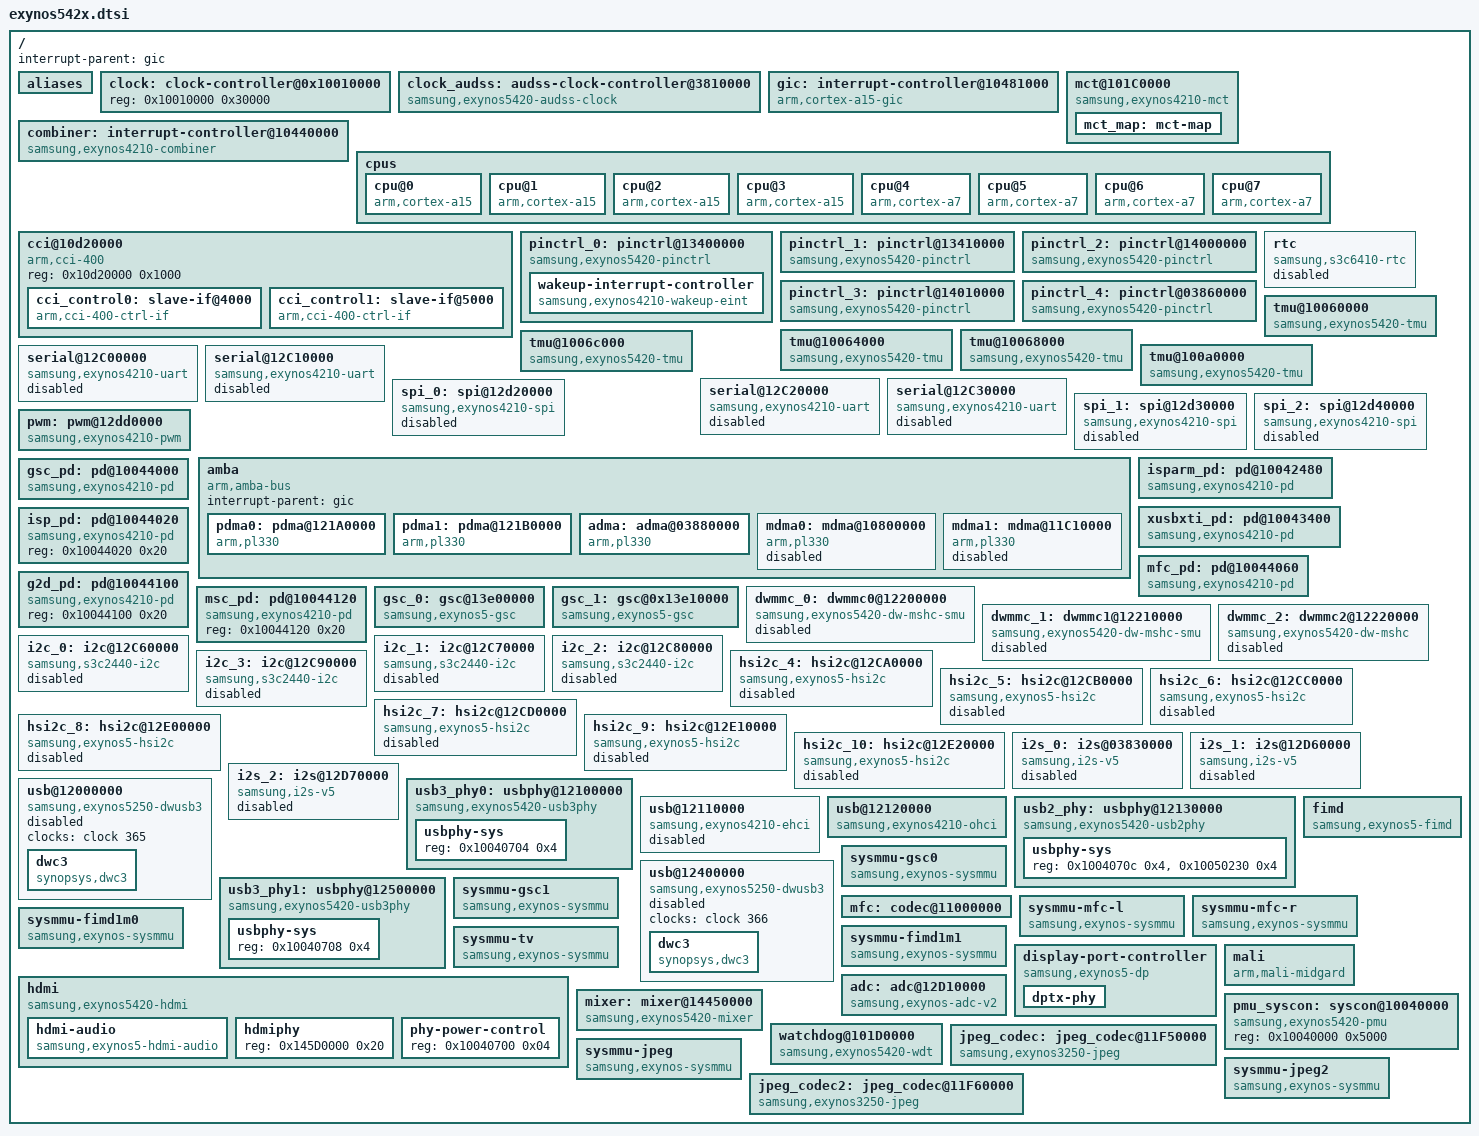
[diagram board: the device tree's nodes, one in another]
/*
 * SAMSUNG EXYNOS542x SoC device tree source
 *
 * Copyright (c) 2013 Samsung Electronics Co., Ltd.
 *		http://www.samsung.com
 *
 * This program is free software; you can redistribute it and/or modify
 * it under the terms of the GNU General Public License version 2 as
 * published by the Free Software Foundation.
*/

#include "skeleton.dtsi"
#include "exynos542x-pinctrl.dtsi"

#include <dt-bindings/clk/exynos-audss-clk.h>

/ {
	interrupt-parent = <&gic>;

	aliases {
		pinctrl0 = &pinctrl_0;
		pinctrl1 = &pinctrl_1;
		pinctrl2 = &pinctrl_2;
		pinctrl3 = &pinctrl_3;
		pinctrl4 = &pinctrl_4;
		mshc0 = &dwmmc_0;
		mshc1 = &dwmmc_1;
		mshc2 = &dwmmc_2;
		gsc0 = &gsc_0;
		gsc1 = &gsc_1;
		i2c0 = &i2c_0;
		i2c1 = &i2c_1;
		i2c2 = &i2c_2;
		i2c3 = &i2c_3;
		i2c4 = &hsi2c_4;
		i2c5 = &hsi2c_5;
		i2c6 = &hsi2c_6;
		i2c7 = &hsi2c_7;
		i2c8 = &hsi2c_8;
		i2c9 = &hsi2c_9;
		i2c10 = &hsi2c_10;
		usb3phy0 = &usb3_phy0;
		usb3phy1 = &usb3_phy1;
		spi0 = &spi_0;
		spi1 = &spi_1;
		spi2 = &spi_2;
	};

	clock: clock-controller@0x10010000 {
		reg = <0x10010000 0x30000>;
		#clock-cells = <1>;
	};

	clock_audss: audss-clock-controller@3810000 {
		compatible = "samsung,exynos5420-audss-clock";
		reg = <0x03810000 0x0C>;
		#clock-cells = <1>;
		clocks = <&clock 148>;
		clock-names = "sclk_audio";
	};

	gic:interrupt-controller@10481000 {
		compatible = "arm,cortex-a15-gic", "arm,cortex-a9-gic";
		#interrupt-cells = <3>;
		#address-cells = <0>;
		#size-cells = <0>;
		interrupt-controller;
		reg = <0x10481000 0x1000>,
		      <0x10482000 0x1000>,
		      <0x10484000 0x2000>,
		      <0x10486000 0x2000>;
		interrupts = <1 9 0xf04>;
	};

	mct@101C0000 {
		compatible = "samsung,exynos4210-mct";
		reg = <0x101C0000 0xb00>;
		interrupt-controller;
		#interrups-cells = <2>;
		interrupt-parent = <&mct_map>;
		interrupts = <0 0>, <1 0>, <2 0>, <3 0>,
			     <4 0>, <5 0>, <6 0>, <7 0>,
			     <8 0>, <9 0>, <10 0>, <11 0>;
		clocks = <&clock 1>, <&clock 315>;
		clock-names = "fin_pll", "mct";

		mct_map: mct-map {
			#interrupt-cells = <2>;
			#address-cells = <0>;
			#size-cells = <0>;
			interrupt-map = <0x0 0 &combiner 23 3>,
					<0x1 0 &combiner 23 4>,
					<0x2 0 &combiner 25 2>,
					<0x3 0 &combiner 25 3>,
					<0x4 0 &gic 0 120 0>,
					<0x5 0 &gic 0 121 0>,
					<0x6 0 &gic 0 122 0>,
					<0x7 0 &gic 0 123 0>,
					<0x8 0 &gic 0 128 0>,
					<0x9 0 &gic 0 129 0>,
					<0xa 0 &gic 0 130 0>,
					<0xb 0 &gic 0 131 0>;
		};
	};

	combiner:interrupt-controller@10440000 {
		compatible = "samsung,exynos4210-combiner";
		#interrupt-cells = <2>;
		interrupt-controller;
		samsung,combiner-nr = <32>;
		reg = <0x10440000 0x1000>;
		interrupts = <0 0 0>, <0 1 0>, <0 2 0>, <0 3 0>,
			     <0 4 0>, <0 5 0>, <0 6 0>, <0 7 0>,
			     <0 8 0>, <0 9 0>, <0 10 0>, <0 11 0>,
			     <0 12 0>, <0 13 0>, <0 14 0>, <0 15 0>,
			     <0 16 0>, <0 17 0>, <0 18 0>, <0 19 0>,
			     <0 20 0>, <0 21 0>, <0 22 0>, <0 23 0>,
			     <0 24 0>, <0 25 0>, <0 26 0>, <0 27 0>,
			     <0 28 0>, <0 29 0>, <0 30 0>, <0 31 0>;
	};

	cpus {
		#address-cells = <1>;
		#size-cells = <0>;

		cpu@0 {
			device_type = "cpu";
			compatible = "arm,cortex-a15";
			reg = <0>;
			cci-control-port = <&cci_control1>;
		};
		cpu@1 {
			device_type = "cpu";
			compatible = "arm,cortex-a15";
			reg = <1>;
			cci-control-port = <&cci_control1>;
		};
		cpu@2 {
			device_type = "cpu";
			compatible = "arm,cortex-a15";
			reg = <2>;
			cci-control-port = <&cci_control1>;
		};
		cpu@3 {
			device_type = "cpu";
			compatible = "arm,cortex-a15";
			reg = <3>;
			cci-control-port = <&cci_control1>;
		};
		cpu@4 {
			device_type = "cpu";
			compatible = "arm,cortex-a7";
			reg = <0x100>;
			cci-control-port = <&cci_control0>;
		};
		cpu@5 {
			device_type = "cpu";
			compatible = "arm,cortex-a7";
			reg = <0x101>;
			cci-control-port = <&cci_control0>;
		};
		cpu@6 {
			device_type = "cpu";
			compatible = "arm,cortex-a7";
			reg = <0x102>;
			cci-control-port = <&cci_control0>;
		};
		cpu@7 {
			device_type = "cpu";
			compatible = "arm,cortex-a7";
			reg = <0x103>;
			cci-control-port = <&cci_control0>;
		};
	};

	cci@10d20000 {
		compatible = "arm,cci-400";
		#address-cells = <1>;
		#size-cells = <1>;
		reg = <0x10d20000 0x1000>;
		ranges = <0x0 0x10d20000 0x6000>;

		cci_control0: slave-if@4000 {
			compatible = "arm,cci-400-ctrl-if";
			interface-type = "ace";
			reg = <0x4000 0x1000>;
		};

		cci_control1: slave-if@5000 {
			compatible = "arm,cci-400-ctrl-if";
			interface-type = "ace";
			reg = <0x5000 0x1000>;
		};
	};

	pinctrl_0: pinctrl@13400000 {
		compatible = "samsung,exynos5420-pinctrl";
		reg = <0x13400000 0x1000>;
		interrupts = <0 45 0>;

		wakeup-interrupt-controller {
			compatible = "samsung,exynos4210-wakeup-eint";
			interrupt-parent = <&gic>;
			interrupts = <0 32 0>;
		};
	};

	pinctrl_1: pinctrl@13410000 {
		compatible = "samsung,exynos5420-pinctrl";
		reg = <0x13410000 0x1000>;
		interrupts = <0 78 0>;
	};

	pinctrl_2: pinctrl@14000000 {
		compatible = "samsung,exynos5420-pinctrl";
		reg = <0x14000000 0x1000>;
		interrupts = <0 46 0>;
	};

	pinctrl_3: pinctrl@14010000 {
		compatible = "samsung,exynos5420-pinctrl";
		reg = <0x14010000 0x1000>;
		interrupts = <0 50 0>;
	};

	pinctrl_4: pinctrl@03860000 {
		compatible = "samsung,exynos5420-pinctrl";
		reg = <0x03860000 0x1000>;
		interrupts = <0 47 0>;
	};

	rtc {
		compatible = "samsung,s3c6410-rtc";
		reg = <0x101E0000 0x100>;
		interrupts = <0 43 0>, <0 44 0>;
		clocks = <&clock 317>;
		clock-names = "rtc";
		status = "disabled";
	};

	/* tmu for CPU0 */
	tmu@10060000 {
		compatible = "samsung,exynos5420-tmu";
		reg = <0x10060000 0x100>;
		interrupts = <0 65 0>;
		clocks = <&clock 318>;
		clock-names = "tmu_apbif";
	};

	/* tmu for CPU1 */
	tmu@10064000 {
		compatible = "samsung,exynos5420-tmu";
		reg = <0x10064000 0x100>;
		interrupts = <0 183 0>;
		clocks = <&clock 318>;
		clock-names = "tmu_apbif";
	};

	/* tmu for CPU2 */
	tmu@10068000 {
		compatible = "samsung,exynos5420-tmu";
		/* 2nd reg is for the misplaced TRIMINFO register */
		reg = <0x10068000 0x100>, <0x1006c000 0x4>;
		interrupts = <0 184 0>;
		clocks = <&clock 318>;
		clock-names = "tmu_apbif";
	};

	/* tmu for CPU3 */
	tmu@1006c000 {
		compatible = "samsung,exynos5420-tmu";
		/* 2nd reg is for the misplaced TRIMINFO register */
		reg = <0x1006c000 0x100>, <0x100a0000 0x4>;
		interrupts = <0 185 0>;
		clocks = <&clock 318>, <&clock 319>;
		clock-names = "tmu_apbif", "tmu_apbif_triminfo";
	};

	/* tmu for GPU */
	tmu@100a0000 {
		compatible = "samsung,exynos5420-tmu";
		/* 2nd reg is for the misplaced TRIMINFO register */
		reg = <0x100a0000 0x100>, <0x10068000 0x4>;
		interrupts = <0 215 0>;
		clocks = <&clock 319>, <&clock 318>;
		clock-names = "tmu_apbif", "tmu_apbif_triminfo";
	};

	serial@12C00000 {
		compatible = "samsung,exynos4210-uart";
		reg = <0x12C00000 0x100>;
		interrupts = <0 51 0>;
		clocks = <&clock 257>, <&clock 128>;
		clock-names = "uart", "clk_uart_baud0";
		status = "disabled";
	};

	serial@12C10000 {
		compatible = "samsung,exynos4210-uart";
		reg = <0x12C10000 0x100>;
		interrupts = <0 52 0>;
		clocks = <&clock 258>, <&clock 129>;
		clock-names = "uart", "clk_uart_baud0";
		status = "disabled";
	};

	serial@12C20000 {
		compatible = "samsung,exynos4210-uart";
		reg = <0x12C20000 0x100>;
		interrupts = <0 53 0>;
		clocks = <&clock 259>, <&clock 130>;
		clock-names = "uart", "clk_uart_baud0";
		status = "disabled";
	};

	serial@12C30000 {
		compatible = "samsung,exynos4210-uart";
		reg = <0x12C30000 0x100>;
		interrupts = <0 54 0>;
		clocks = <&clock 260>, <&clock 131>;
		clock-names = "uart", "clk_uart_baud0";
		status = "disabled";
	};

	spi_0: spi@12d20000 {
		compatible = "samsung,exynos4210-spi";
		reg = <0x12d20000 0x100>;
		interrupts = <0 66 0>;
		dmas = <&pdma0 5
			&pdma0 4>;
		dma-names = "tx", "rx";
		#address-cells = <1>;
		#size-cells = <0>;
		pinctrl-names = "default";
		pinctrl-0 = <&spi0_bus>;
		clocks = <&clock 271>, <&clock 135>;
		clock-names = "spi", "spi_busclk0";
		status = "disabled";
	};

	spi_1: spi@12d30000 {
		compatible = "samsung,exynos4210-spi";
		reg = <0x12d30000 0x100>;
		interrupts = <0 67 0>;
		dmas = <&pdma1 5
			&pdma1 4>;
		dma-names = "tx", "rx";
		#address-cells = <1>;
		#size-cells = <0>;
		pinctrl-names = "default";
		pinctrl-0 = <&spi1_bus>;
		clocks = <&clock 272>, <&clock 136>;
		clock-names = "spi", "spi_busclk0";
		status = "disabled";
	};

	spi_2: spi@12d40000 {
		compatible = "samsung,exynos4210-spi";
		reg = <0x12d40000 0x100>;
		interrupts = <0 68 0>;
		dmas = <&pdma0 7
			&pdma0 6>;
		dma-names = "tx", "rx";
		#address-cells = <1>;
		#size-cells = <0>;
		pinctrl-names = "default";
		pinctrl-0 = <&spi2_bus>;
		clocks = <&clock 273>, <&clock 137>;
		clock-names = "spi", "spi_busclk0";
		status = "disabled";
	};

	pwm: pwm@12dd0000 {
		compatible = "samsung,exynos4210-pwm";
		reg = <0x12dd0000 0x100>;
		samsung,pwm-outputs = <0>, <1>, <2>, <3>;
		#pwm-cells = <3>;
		clocks = <&clock 278>;
		clock-names = "timers";
	};

	amba {
		#address-cells = <1>;
		#size-cells = <1>;
		compatible = "arm,amba-bus";
		interrupt-parent = <&gic>;
		ranges;

		pdma0: pdma@121A0000 {
			compatible = "arm,pl330", "arm,primecell";
			reg = <0x121A0000 0x1000>;
			interrupts = <0 34 0>;
			clocks = <&clock 361>;
			clock-names = "apb_pclk";
			#dma-cells = <1>;
			#dma-channels = <8>;
			#dma-requests = <32>;
		};

		pdma1: pdma@121B0000 {
			compatible = "arm,pl330", "arm,primecell";
			reg = <0x121B0000 0x1000>;
			interrupts = <0 35 0>;
			clocks = <&clock 362>;
			clock-names = "apb_pclk";
			#dma-cells = <1>;
			#dma-channels = <8>;
			#dma-requests = <32>;
		};

		adma: adma@03880000 {
			compatible = "arm,pl330", "arm,primecell";
			reg = <0x03880000 0x1000>;
			interrupts = <0 110 0>;
			clocks = <&clock_audss EXYNOS_ADMA>;
			clock-names = "apb_pclk";
			#dma-cells = <1>;
			#dma-channels = <6>;
			#dma-requests = <16>;
		};

		mdma0: mdma@10800000 {
			compatible = "arm,pl330", "arm,primecell";
			reg = <0x10800000 0x1000>;
			interrupts = <0 33 0>;
			clocks = <&clock 473>;
			clock-names = "apb_pclk";
			#dma-cells = <1>;
			#dma-channels = <8>;
			#dma-requests = <1>;
			status = "disabled";
		};

		mdma1: mdma@11C10000 {
			compatible = "arm,pl330", "arm,primecell";
			reg = <0x11C10000 0x1000>;
			interrupts = <0 124 0>;
			clocks = <&clock 442>;
			clock-names = "apb_pclk";
			#dma-cells = <1>;
			#dma-channels = <8>;
			#dma-requests = <1>;
			status = "disabled";
		};
	};

	isparm_pd: pd@10042480 {
		compatible = "samsung,exynos4210-pd";
		reg = <0x10042480 0x20>;
		enable = <0x1>;
	};

	xusbxti_pd: pd@10043400 {
		compatible = "samsung,exynos4210-pd";
		reg = <0x10043400 0x20>;
		enable = <0x1>;
	};

	gsc_pd: pd@10044000 {
		compatible = "samsung,exynos4210-pd";
		reg = <0x10044000 0x20>;
		clocks = <&clock 1>, <&clock 1032>, <&clock 1033>,
			 <&clock 2050>, <&clock 1034>, <&clock 1035>,
			 <&clock 2051>;
		clock-names = "oscclk", "pclk0", "clk0", "dclk0",
			      "pclk1", "clk1", "dclk1";
	};

	isp_pd: pd@10044020 {
		compatible = "samsung,exynos4210-pd";
		reg = <0x10044020 0x20>;
	};

	mfc_pd: pd@10044060 {
		compatible = "samsung,exynos4210-pd";
		reg = <0x10044060 0x20>;
		clocks = <&clock 1>, <&clock 1030>, <&clock 1031>,
			 <&clock 2049>;
		clock-names = "oscclk", "pclk0", "clk0" , "dclk0";
	};

	g2d_pd: pd@10044100 {
		compatible = "samsung,exynos4210-pd";
		reg = <0x10044100 0x20>;
	};

	msc_pd: pd@10044120 {
		compatible = "samsung,exynos4210-pd";
		reg = <0x10044120 0x20>;
	};

	gsc_0:  gsc@13e00000 {
		compatible = "samsung,exynos5-gsc";
		reg = <0x13e00000 0x1000>;
		interrupts = <0 85 0>;
		clocks = <&clock 465>;
		clock-names = "gscl";
		samsung,power-domain = <&gsc_pd>;
	};

	gsc_1:  gsc@0x13e10000 {
		compatible = "samsung,exynos5-gsc";
		reg = <0x13e10000 0x1000>;
		interrupts = <0 86 0>;
		clocks = <&clock 466>;
		clock-names = "gscl";
		samsung,power-domain = <&gsc_pd>;
	};

	dwmmc_0: dwmmc0@12200000 {
		compatible = "samsung,exynos5420-dw-mshc-smu";
		reg = <0x12200000 0x2000>;
		interrupts = <0 75 0>;
		#address-cells = <1>;
		#size-cells = <0>;
		clocks = <&clock 351>, <&clock 132>;
		clock-names = "biu", "ciu";
		status = "disabled";
	};

	dwmmc_1: dwmmc1@12210000 {
		compatible = "samsung,exynos5420-dw-mshc-smu";
		reg = <0x12210000 0x2000>;
		interrupts = <0 76 0>;
		#address-cells = <1>;
		#size-cells = <0>;
		clocks = <&clock 352>, <&clock 133>;
		clock-names = "biu", "ciu";
		status = "disabled";
	};

	dwmmc_2: dwmmc2@12220000 {
		compatible = "samsung,exynos5420-dw-mshc";
		reg = <0x12220000 0x1000>;
		interrupts = <0 77 0>;
		#address-cells = <1>;
		#size-cells = <0>;
		clocks = <&clock 353>, <&clock 134>;
		clock-names = "biu", "ciu";
		status = "disabled";
	};

	i2c_0: i2c@12C60000 {
		compatible = "samsung,s3c2440-i2c";
		reg = <0x12C60000 0x100>;
		interrupts = <0 56 0>;
		#address-cells = <1>;
		#size-cells = <0>;
		pinctrl-names = "default";
		pinctrl-0 = <&i2c0_bus>;
		clocks = <&clock 261>;
		clock-names = "i2c";
		status = "disabled";
	};

	i2c_1: i2c@12C70000 {
		compatible = "samsung,s3c2440-i2c";
		reg = <0x12C70000 0x100>;
		interrupts = <0 57 0>;
		#address-cells = <1>;
		#size-cells = <0>;
		pinctrl-names = "default";
		pinctrl-0 = <&i2c1_bus>;
		clocks = <&clock 262>;
		clock-names = "i2c";
		status = "disabled";
	};

	i2c_2: i2c@12C80000 {
		compatible = "samsung,s3c2440-i2c";
		reg = <0x12C80000 0x100>;
		interrupts = <0 58 0>;
		#address-cells = <1>;
		#size-cells = <0>;
		pinctrl-names = "default";
		pinctrl-0 = <&i2c2_bus>;
		clocks = <&clock 263>;
		clock-names = "i2c";
		status = "disabled";
	};

	i2c_3: i2c@12C90000 {
		compatible = "samsung,s3c2440-i2c";
		reg = <0x12C90000 0x100>;
		interrupts = <0 59 0>;
		#address-cells = <1>;
		#size-cells = <0>;
		pinctrl-names = "default";
		pinctrl-0 = <&i2c3_bus>;
		clocks = <&clock 264>;
		clock-names = "i2c";
		status = "disabled";
	};

	hsi2c_4: hsi2c@12CA0000 {
		compatible = "samsung,exynos5-hsi2c";
		reg = <0x12CA0000 0x1000>;
		interrupts = <0 60 0>;
		#address-cells = <1>;
		#size-cells = <0>;
		pinctrl-names = "default";
		pinctrl-0 = <&i2c4_hs_bus>;
		clocks = <&clock 265>;
		clock-names = "hsi2c";
		status = "disabled";
	};

	hsi2c_5: hsi2c@12CB0000 {
		compatible = "samsung,exynos5-hsi2c";
		reg = <0x12CB0000 0x1000>;
		interrupts = <0 61 0>;
		#address-cells = <1>;
		#size-cells = <0>;
		pinctrl-names = "default";
		pinctrl-0 = <&i2c5_hs_bus>;
		clocks = <&clock 266>;
		clock-names = "hsi2c";
		status = "disabled";
	};

	hsi2c_6: hsi2c@12CC0000 {
		compatible = "samsung,exynos5-hsi2c";
		reg = <0x12CC0000 0x1000>;
		interrupts = <0 62 0>;
		#address-cells = <1>;
		#size-cells = <0>;
		pinctrl-names = "default";
		pinctrl-0 = <&i2c6_hs_bus>;
		clocks = <&clock 267>;
		clock-names = "hsi2c";
		status = "disabled";
	};

	hsi2c_7: hsi2c@12CD0000 {
		compatible = "samsung,exynos5-hsi2c";
		reg = <0x12CD0000 0x1000>;
		interrupts = <0 63 0>;
		#address-cells = <1>;
		#size-cells = <0>;
		pinctrl-names = "default";
		pinctrl-0 = <&i2c7_hs_bus>;
		clocks = <&clock 268>;
		clock-names = "hsi2c";
		status = "disabled";
	};

	hsi2c_8: hsi2c@12E00000 {
		compatible = "samsung,exynos5-hsi2c";
		reg = <0x12E00000 0x1000>;
		interrupts = <0 87 0>;
		#address-cells = <1>;
		#size-cells = <0>;
		pinctrl-names = "default";
		pinctrl-0 = <&i2c8_hs_bus>;
		clocks = <&clock 280>;
		clock-names = "hsi2c";
		status = "disabled";
	};

	hsi2c_9: hsi2c@12E10000 {
		compatible = "samsung,exynos5-hsi2c";
		reg = <0x12E10000 0x1000>;
		interrupts = <0 88 0>;
		#address-cells = <1>;
		#size-cells = <0>;
		pinctrl-names = "default";
		pinctrl-0 = <&i2c9_hs_bus>;
		clocks = <&clock 281>;
		clock-names = "hsi2c";
		status = "disabled";
	};

	hsi2c_10: hsi2c@12E20000 {
		compatible = "samsung,exynos5-hsi2c";
		reg = <0x12E20000 0x1000>;
		interrupts = <0 203 0>;
		#address-cells = <1>;
		#size-cells = <0>;
		pinctrl-names = "default";
		pinctrl-0 = <&i2c10_hs_bus>;
		clocks = <&clock 282>;
		clock-names = "hsi2c";
		status = "disabled";
	};

	i2s_0: i2s@03830000 {
		compatible = "samsung,i2s-v5";
		reg = <0x03830000 0x100>;
		dmas = <&adma 0
			&adma 2
			&adma 1>;
		dma-names = "tx", "rx", "tx-sec";
		clocks = <&clock_audss EXYNOS_I2S_BUS>,
			<&clock_audss EXYNOS_I2S_BUS>,
			<&clock_audss EXYNOS_SCLK_I2S>;
		clock-names = "iis", "i2s_opclk0", "i2s_opclk1";
		samsung,supports-6ch;
		samsung,supports-rstclr;
		samsung,supports-secdai;
		samsung,supports-tdm;
		samsung,idma-addr = <0x03000000>;
		pinctrl-names = "default";
		pinctrl-0 = <&i2s0_bus>;
		status = "disabled";
	};

	i2s_1: i2s@12D60000 {
		compatible = "samsung,i2s-v5";
		reg = <0x12D60000 0x100>;
		dmas = <&pdma1 12
			&pdma1 11>;
		dma-names = "tx", "rx";
		clocks = <&clock 274>, <&clock 138>;
		clock-names = "iis", "i2s_opclk0";
		pinctrl-names = "default";
		pinctrl-0 = <&i2s1_bus>;
		status = "disabled";
	};

	i2s_2: i2s@12D70000 {
		compatible = "samsung,i2s-v5";
		reg = <0x12D70000 0x100>;
		dmas = <&pdma0 12
			&pdma0 11>;
		dma-names = "tx", "rx";
		clocks = <&clock 275>, <&clock 139>;
		clock-names = "iis", "i2s_opclk0";
		pinctrl-names = "default";
		pinctrl-0 = <&i2s2_bus>;
		status = "disabled";
	};

	usb@12000000 {
		compatible = "samsung,exynos5250-dwusb3";
		clocks = <&clock 365>;
		clock-names = "usbdrd30";
		#address-cells = <1>;
		#size-cells = <1>;
		ranges;
		status = "disabled";

		dwc3 {
			compatible = "synopsys,dwc3";
			reg = <0x12000000 0x10000>;
			interrupts = <0 72 0>;
			usb3-phy = <&usb3_phy0>;
		};
	};

	usb3_phy0: usbphy@12100000 {
		compatible = "samsung,exynos5420-usb3phy";
		reg = <0x12100000 0x100>;
		clocks = <&clock 1>, <&clock 365>;
		clock-names = "ext_xtal", "usbdrd30";
		#address-cells = <1>;
		#size-cells = <1>;
		ranges;

		usbphy-sys {
			reg = <0x10040704 0x4>;
		};
	};

	usb@12110000 {
		compatible = "samsung,exynos4210-ehci";
		reg = <0x12110000 0x100>;
		interrupts = <0 71 0>;
		clocks = <&clock 364>;
		clock-names = "usbhost";
		status = "disabled";
	};

	usb@12120000 {
		compatible = "samsung,exynos4210-ohci";
		reg = <0x12120000 0x100>;
		interrupts = <0 71 0>;
		clocks = <&clock 364>;
		clock-names = "usbhost";
	};

	usb2_phy: usbphy@12130000 {
		compatible = "samsung,exynos5420-usb2phy";
		reg = <0x12130000 0x100>;
		clocks = <&clock 1>, <&clock 364>;
		clock-names = "ext_xtal", "usbhost";
		#address-cells = <1>;
		#size-cells = <1>;
		ranges;

		usbphy-sys {
			reg = <0x1004070c 0x4>,
			      <0x10050230 0x4>;
		};
	};

	usb@12400000 {
		compatible = "samsung,exynos5250-dwusb3";
		clocks = <&clock 366>;
		clock-names = "usbdrd30";
		#address-cells = <1>;
		#size-cells = <1>;
		ranges;
		status = "disabled";

		dwc3 {
			compatible = "synopsys,dwc3";
			reg = <0x12400000 0x10000>;
			interrupts = <0 73 0>;
			usb3-phy = <&usb3_phy1>;
		};
	};

	usb3_phy1: usbphy@12500000 {
		compatible = "samsung,exynos5420-usb3phy";
		reg = <0x12500000 0x100>;
		clocks = <&clock 1>, <&clock 366>;
		clock-names = "ext_xtal", "usbdrd30";
		#address-cells = <1>;
		#size-cells = <1>;
		ranges;

		usbphy-sys {
			reg = <0x10040708 0x4>;
		};
	};

	fimd: fimd {
		compatible = "samsung,exynos5-fimd";
		interrupt-parent = <&combiner>;
		reg = <0x14400000 0x40000>;
		interrupts = <18 5>, <18 4>, <18 6>;
		clocks = <&clock 147>, <&clock 421>, <&clock 1024>,
							<&clock 2>;
		clock-names = "sclk_fimd", "fimd", "mout_fimd",
							"sclk_mout_fimd";
	};

	sysmmu-gsc0 {
		mmuname = "gsc0";
		reg = <0x13E80000 0x1000>;
		compatible = "samsung,exynos-sysmmu";
		interrupt-parent = <&combiner>;
		interrupts = <2 0>;
		mmu-master = <&gsc_0>;
		clocks = <&clock 461>, <&clock 465>;
		clock-names = "sysmmu", "master";
		samsung,power-domain = <&gsc_pd>;
	};

	sysmmu-gsc1 {
		mmuname = "gsc1";
		reg = <0x13E90000 0x1000>;
		compatible = "samsung,exynos-sysmmu";
		interrupt-parent = <&combiner>;
		interrupts = <2 2>;
		mmu-master = <&gsc_1>;
		clocks = <&clock 462>, <&clock 466>;
		clock-names = "sysmmu", "master";
		samsung,power-domain = <&gsc_pd>;
	};

	mfc: codec@11000000 {
		reg = <0x11000000 0x10000>;
		interrupts = <0 96 0>;
		clocks = <&clock 401>;
		clock-names = "mfc";
		samsung,power-domain = <&mfc_pd>;
	};

	sysmmu-mfc-l {
		mmuname = "mfc_l";
		reg = <0x11200000 0x1000>;
		compatible = "samsung,exynos-sysmmu";
		interrupt-parent = <&combiner>;
		interrupts = <8 5>;
		mmu-master = <&mfc>;
		clocks = <&clock 402>, <&clock 401>;
		clock-names = "sysmmu", "master";
		samsung,power-domain = <&mfc_pd>;
	};

	sysmmu-mfc-r {
		mmuname = "mfc_r";
		reg = <0x11210000 0x1000>;
		compatible = "samsung,exynos-sysmmu";
		interrupt-parent = <&combiner>;
		interrupts = <6 2>;
		mmu-master = <&mfc>;
		clocks = <&clock 403>, <&clock 401>;
		clock-names = "sysmmu", "master";
		samsung,power-domain = <&mfc_pd>;
	};

	sysmmu-fimd1m0 {
		mmuname = "fimd1m0";
		reg = <0x14640000 0x1000>;
		compatible = "samsung,exynos-sysmmu";
		interrupt-parent = <&combiner>;
		interrupts = <3 2>;
		mmu-master = <&fimd>;
		clocks = <&clock 422>, <&clock 421>;
		clock-names = "sysmmu", "master";
	};

	sysmmu-fimd1m1 {
		mmuname = "fimd1m1";
		reg = <0x14680000 0x1000>;
		compatible = "samsung,exynos-sysmmu";
		interrupt-parent = <&combiner>;
		interrupts = <3 0>;
		mmu-master = <&fimd>;
		clocks = <&clock 423>, <&clock 421>;
		clock-names = "sysmmu", "master";
	};

	sysmmu-tv {
		mmuname = "tv";
		reg = <0x14650000 0x1000>;
		compatible = "samsung,exynos-sysmmu";
		interrupt-parent = <&combiner>;
		interrupts = <7 4>;
		mmu-master = <&mixer>;
		clocks = <&clock 501>;
		clock-names = "sysmmu";
	};

	display-port-controller {
		compatible = "samsung,exynos5-dp";
		reg = <0x145b0000 0x1000>;
		interrupts = <10 3>;
		interrupt-parent = <&combiner>;
		clocks = <&clock 412>;
		clock-names = "dp";
		#address-cells = <1>;
		#size-cells = <0>;

		dptx-phy {
			reg = <0x10040728>;
			samsung,enable-mask = <1>;
		};
	};

	mali {
		compatible = "arm,mali-midgard";
		reg = <0x11800000 0x5000>;
		interrupts = <0 219 0>, <0 74 0>, <0 117 0>;
		interrupt-names = "JOB", "MMU", "GPU";
		clocks = <&clock 500>, <&clock 1036>, <&clock 6>, <&clock 1>,
			<&clock 7>;
		clock-names = "g3d", "aclk_g3d", "mout_vpll", "ext_xtal",
			"fout_vpll";
	};

	hdmi {
		compatible = "samsung,exynos5420-hdmi";
		reg = <0x14530000 0x70000>, <0x10040700 0x4>;
		clocks = <&clock 413>, <&clock 143>, <&clock 2048>,
			<&clock 158>, <&clock 1026>;
		clock-names = "hdmi", "sclk_hdmi", "sclk_pixel",
			"sclk_hdmiphy", "mout_hdmi";
		interrupts = <0 95 0>;
		#address-cells = <1>;
		#size-cells = <1>;

		hdmi-audio {
			compatible = "samsung,exynos5-hdmi-audio";
		};

		hdmiphy {
			reg = <0x145D0000 0x20>;
		};

		phy-power-control {
			reg = <0x10040700 0x04>;
		};
	};

	mixer: mixer@14450000 {
		compatible = "samsung,exynos5420-mixer";
		reg = <0x14450000 0x10000>;
		interrupts = <0 94 0>;
		clocks = <&clock 431>, <&clock 143>;
		clock-names = "mixer", "sclk_hdmi";
	};

	adc: adc@12D10000 {
		compatible = "samsung,exynos-adc-v2";
		reg = <0x12D10000 0x100>, <0x10040720 0x4>;
		interrupts = <0 106 0>;
		#io-channel-cells = <1>;
		io-channel-ranges;
		clocks = <&clock 270>;
		clock-names = "adc";
	};

	pmu_syscon: syscon@10040000 {
		compatible = "samsung,exynos5420-pmu", "syscon";
		reg = <0x10040000 0x5000>;
	};

        watchdog@101D0000 {
		compatible = "samsung,exynos5420-wdt";
		reg = <0x101D0000 0x100>;
		interrupts = <0 42 0>;
		clocks = <&clock 316>;
		clock-names = "watchdog";
		samsung,syscon-phandle = <&pmu_syscon>;
        };

	jpeg_codec: jpeg_codec@11F50000 {
		compatible = "samsung,exynos3250-jpeg";
		reg = <0x11F50000 0x1000>;
		interrupts = <0 89 0>;
		clocks = <&clock 451>;
		clock-names = "jpeg";
		status = "ok";
	};

	sysmmu-jpeg {
		mmuname = "jpeg";
		reg = <0x11F10000 0x1000>;
		compatible = "samsung,exynos-sysmmu";
		interrupt-parent = <&combiner>;
		interrupts = <4 2>;
		mmu-master = <&jpeg_codec>;
		clocks = <&clock 453>, <&clock 451>;
		clock-names = "sysmmu", "master";
	};

	jpeg_codec2: jpeg_codec@11F60000 {
		compatible = "samsung,exynos3250-jpeg";
		reg = <0x11F60000 0x1000>;
		interrupts = <0 168 0>;
		clocks = <&clock 452>;
		clock-names = "jpeg";
		status = "ok";
	};

	sysmmu-jpeg2 {
		mmuname = "jpeg2";
		reg = <0x11F20000 0x1000>;
		compatible = "samsung,exynos-sysmmu";
		interrupts = <0 169 0>;
		mmu-master = <&jpeg_codec2>;
		clocks = <&clock 506>, <&clock 452>;
		clock-names = "sysmmu", "master";
	};
};
